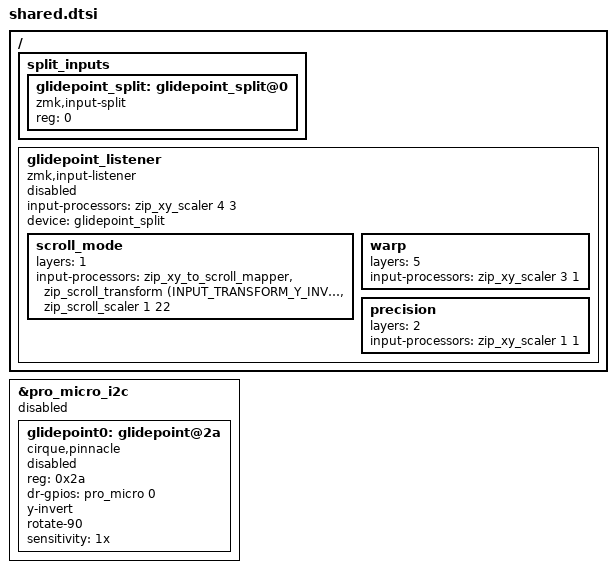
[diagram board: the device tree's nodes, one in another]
#include <dt-bindings/zmk/pointing.h>
#include <input/processors.dtsi>
#include <zephyr/dt-bindings/input/input-event-codes.h>
#include <dt-bindings/zmk/input_transform.h>

&pro_micro_i2c {
    status = "disabled";
    glidepoint0: glidepoint@2a {
        compatible = "cirque,pinnacle";
        reg = <0x2a>;
        status = "disabled";
        dr-gpios = <&pro_micro 0 (GPIO_ACTIVE_HIGH)>;
        y-invert;
        rotate-90;

        sensitivity = "1x";
    };
};

/ {
    split_inputs {
        #address-cells = <1>;
        #size-cells = <0>;

        glidepoint_split: glidepoint_split@0 {
            compatible = "zmk,input-split";
            reg = <0>;
        };
    };

    glidepoint_listener: glidepoint_listener {
        compatible = "zmk,input-listener";
        input-processors = <&zip_xy_scaler 4 3>;
        status = "disabled";
        device = <&glidepoint_split>;
        
        // Scroll setup using layer override
        scroll_mode {
            layers = <1>;  // Use layer 2 for scrolling
            input-processors = <&zip_xy_to_scroll_mapper>, <&zip_scroll_transform (INPUT_TRANSFORM_Y_INVERT | INPUT_TRANSFORM_X_INVERT)>, <&zip_scroll_scaler 1 22>;
        };

        // Fast movement mode (warp)
        warp {
            layers = <5>;  // Use layer 5 for warp functionality (fast movement)
            input-processors = <&zip_xy_scaler 3 1>;
        };

        // Precision mode for slower movement
        precision {
            layers = <2>;
            input-processors = <&zip_xy_scaler 1 1>;
        };
    };
};
